CM_ "This DBC is used for the CAN parser and packer tests.";

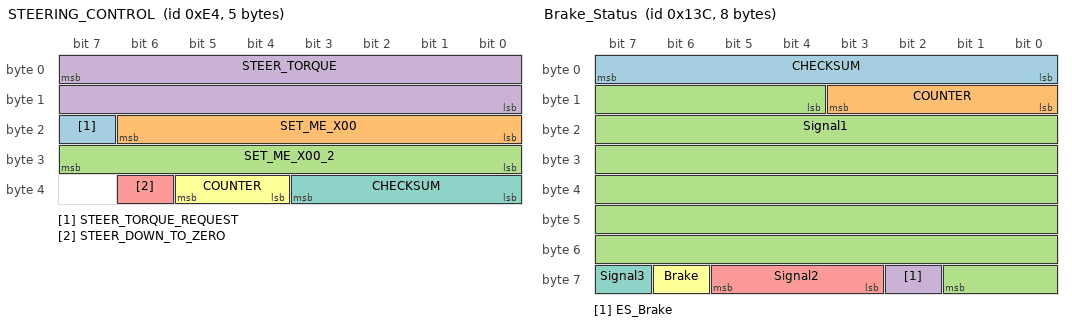
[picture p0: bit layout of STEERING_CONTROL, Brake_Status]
BO_ 228 STEERING_CONTROL: 5 EON
 SG_ STEER_TORQUE_REQUEST : 23|1@0+ (1,0) [0|1] "" EPS
 SG_ SET_ME_X00 : 22|7@0+ (1,0) [0|127] "" EPS
 SG_ SET_ME_X00_2 : 31|8@0+ (1,0) [0|0] "" EPS
 SG_ STEER_TORQUE : 7|16@0- (1,0) [-4096|4096] "" EPS
 SG_ STEER_DOWN_TO_ZERO : 38|1@0+ (1,0) [0|1] "" EPS
 SG_ COUNTER : 37|2@0+ (1,0) [0|3] "" EPS
 SG_ CHECKSUM : 35|4@0+ (1,0) [0|15] "" EPS

BO_ 316 Brake_Status: 8 XXX
 SG_ CHECKSUM : 0|8@1+ (1,0) [0|255] "" XXX
 SG_ COUNTER : 8|4@1+ (1,0) [0|15] "" XXX
 SG_ Signal1 : 12|46@1+ (1,0) [0|1] "" XXX
 SG_ ES_Brake : 58|1@1+ (1,0) [0|1] "" XXX
 SG_ Signal2 : 59|3@1+ (1,0) [0|1] "" XXX
 SG_ Brake : 62|1@1+ (1,0) [0|1] "" XXX
 SG_ Signal3 : 63|1@1+ (1,0) [0|1] "" XXX

BO_ 245 CAN_FD_MESSAGE: 32 XXX
 SG_ COUNTER : 7|8@0+ (1,0) [0|1] "" XXX
 SG_ SIGNED : 22|16@0- (1,0) [0|1] "" XXX
 SG_ 64_BIT_LE : 159|64@1+ (1,0) [0|1] "" XXX
 SG_ 64_BIT_BE : 80|64@0+ (1,0) [0|1] "" XXX

VAL_ 80 NON_EXISTENT_ADDR 0 "test";

BA_DEF_ BO_ "GenMsgCycleTime" INT 0 65535;
BA_DEF_ BO_ "SecOCKeyRole" STRING;
BA_DEF_ BO_ "Ratio" FLOAT 0 1;
BA_DEF_ SG_ "SigStartValue" INT 0 100;
BA_DEF_ "BusType" STRING;
BA_DEF_DEF_ "GenMsgCycleTime" 0;
BA_ "BusType" "CAN";
BA_ "GenMsgCycleTime" BO_ 228 10;
BA_ "SecOCKeyRole" BO_ 228 "test_key";
BA_ "Ratio" BO_ 228 0.5;
BA_ "SigStartValue" SG_ 228 STEER_TORQUE 5;
